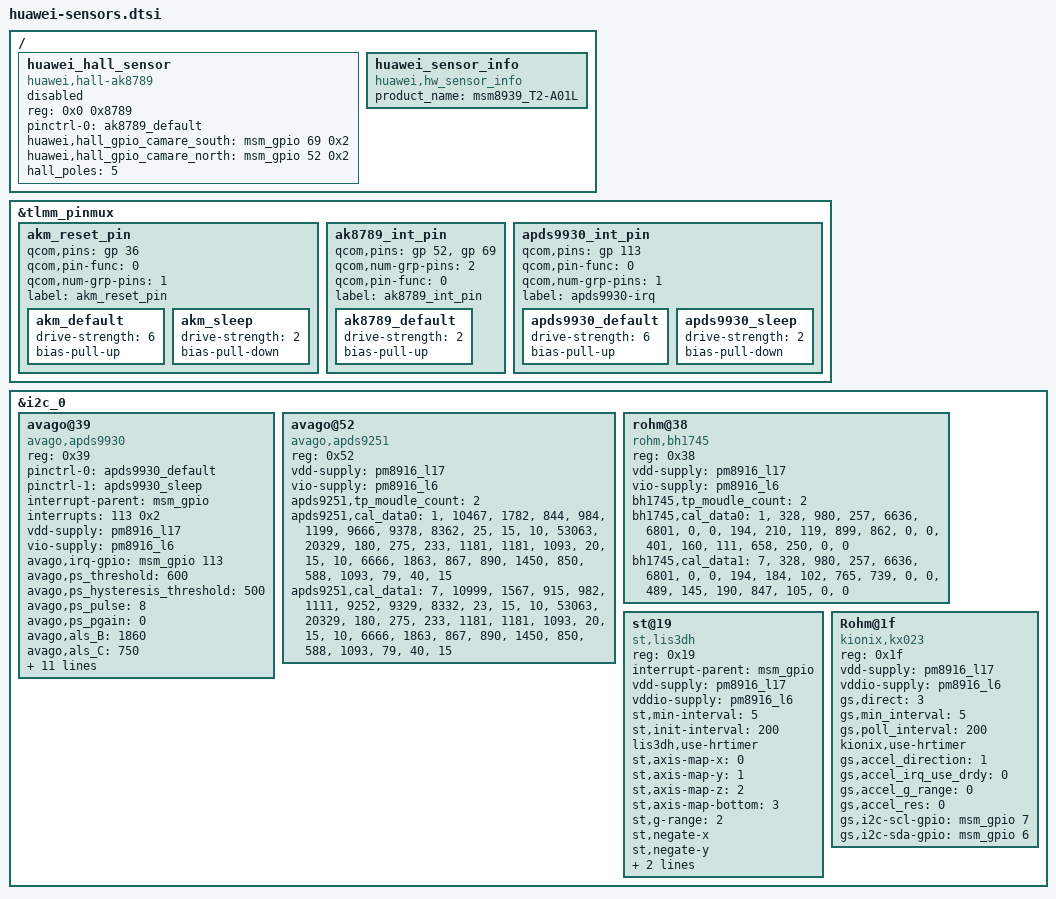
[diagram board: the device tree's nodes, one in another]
/* < DTS2015071605523 guotiecheng 20150716 begin */
/*use fromdos convert file format to linux*/
/* Copyright (c) 2013 The Linux Foundation. All rights reserved.
 *
 * This program is free software; you can redistribute it and/or modify
 * it under the terms of the GNU General Public License version 2 and
 * only version 2 as published by the Free Software Foundation.
 *
 * This program is distributed in the hope that it will be useful,
 * but WITHOUT ANY WARRANTY; without even the implied warranty of
 * MERCHANTABILITY or FITNESS FOR A PARTICULAR PURPOSE.  See the
 * GNU General Public License for more details.
 */
&tlmm_pinmux {
	akm_reset_pin {
		qcom,pins = <&gp 36>;
		qcom,pin-func = <0>;
		qcom,num-grp-pins = <1>;
		label = "akm_reset_pin";
		akm_default: akm_default {
			drive-strength = <6>;
			bias-pull-up;
		};
		akm_sleep: akm_sleep {
			drive-strength = <2>;
			bias-pull-down;
		};
	};

/* DTS2015012910874 dingjingfeng 20150206 begin> */
//delete lines
/* DTS2015012910874 dingjingfeng 20150206 end> */
	ak8789_int_pin {
		qcom,pins = <&gp 52>, <&gp 69>;
		qcom,num-grp-pins = <2>;
		qcom,pin-func = <0>;
		label = "ak8789_int_pin";
		ak8789_default: ak8789_default {
			  drive-strength = <2>;
			  bias-pull-up;
		};
	};
	apds9930_int_pin {
		qcom,pins = <&gp 113>;
		qcom,pin-func = <0>;
		qcom,num-grp-pins = <1>;
		label = "apds9930-irq";
		apds9930_default: apds9930_default {
			drive-strength = <6>;
			bias-pull-up;
		};
		apds9930_sleep: apds9930_sleep {
			drive-strength = <2>;
			bias-pull-down;
		};
	};
	/*<DTS2015072101855 chendong cwx241705 begin  */
	//delete
	/*DTS2015072101855 chendong cwx241705 end>  */
/* < DTS2015011203894 Zhangbo 00166742 20150112 begin */
/* delete some lines */
/* DTS2015011203894 Zhangbo 00166742 20150112 end > */
};

&i2c_0 { /* BLSP1 QUP2 */
	/* < DTS2015120500346  chendong 20151126 begin */
	//delete line
	/* DTS2015120500346  chendong 20151126 end > */
	avago@39 {
		compatible = "avago,apds9930";
		reg = <0x39>;
		pinctrl-names = "default","sleep";
		pinctrl-0 = <&apds9930_default>;
		pinctrl-1 = <&apds9930_sleep>;
		interrupt-parent = <&msm_gpio>;
		interrupts = <113 0x2>;
		vdd-supply = <&pm8916_l17>;
		vio-supply = <&pm8916_l6>;
		avago,irq-gpio = <&msm_gpio 113 0x2>;
		avago,ps_threshold = <600>;
		avago,ps_hysteresis_threshold = <500>;
		avago,ps_pulse = <8>;
		avago,ps_pgain = <0>;
		avago,als_B = <1860>;
		avago,als_C = <750>;
		avago,als_D = <1290>;
		avago,ga_value = <48>;
	        avago,ga_a_value = <112>;
		avago,ga_c_value = <450>;
		avago,ga_d_value = <162>;
		avago,window = <110>;
		avago,wave = <84>;
		avago,ga_e_value = <220>;
		avago,ga_f_value = <43>;
		/* < DTS2015032800844 caowei 20150319 begin */
		avago,i2c-scl-gpio = <&msm_gpio 7 0x0>;
		avago,i2c-sda-gpio = <&msm_gpio 6 0x0>;
		/* DTS2015032800844 caowei 20150319 end > */
	};
/* < DTS2015081407714 chendong wx241705 begin */
/* < DTS2015120303924 liuanqi wx319287 begin */
/* < DTS2016011800604  liuanqi lwx319287 begin */
	avago@52 {
		compatible = "avago,apds9251";
		reg = <0x52>;
		vdd-supply = <&pm8916_l17>;
		vio-supply = <&pm8916_l6>;
		apds9251,tp_moudle_count = <2>;
		/*[module_id] gold [CCT_M] [CCT_N] [H] [A] [D] [LUX_P] [LUX_Q] [LUX_R] [cofficient0] [cofficient1] [cofficient2]*/
		apds9251,cal_data0 = "1","10467","1782","844","984","1199","9666","9378","8362","25","15","10",
		/*white [CCT_M] [CCT_N] [H] [A] [D] [LUX_P] [LUX_Q] [LUX_R] [cofficient0] [cofficient1] [cofficient2]*/
		"53063","20329","180","275","233","1181","1181","1093","20","15","10",
		/*black [CCT_M] [CCT_N] [H] [A] [D] [LUX_P] [LUX_Q] [LUX_R] [cofficient0] [cofficient1] [cofficient2]*/
		"6666","1863","867","890","1450","850","588","1093","79","40","15";
		/*[module_id] [CCT_M] [CCT_N] [H] [A] [D] [LUX_P] [LUX_Q] [LUX_R] [cofficient0] [cofficient1] [cofficient2]*/
		apds9251,cal_data1 = "7","10999","1567","915","982","1111","9252","9329","8332","23","15","10",
		/*[CCT_M] [CCT_N] [H] [A] [D] [LUX_P] [LUX_Q] [LUX_R] [cofficient0] [cofficient1] [cofficient2]*/
		"53063","20329","180","275","233","1181","1181","1093","20","15","10",
		/*[CCT_M] [CCT_N] [H] [A] [D] [LUX_P] [LUX_Q] [LUX_R] [cofficient0] [cofficient1] [cofficient2]*/
		"6666","1863","867","890","1450","850","588","1093","79","40","15";
	};
/* DTS2015081407714 chendong wx241705 end > */
	/*<DTS2015072101855 chendong cwx241705 begin  */
	rohm@38 {
	compatible = "rohm,bh1745";
	reg = <0x38>;
	vdd-supply = <&pm8916_l17>;
	vio-supply = <&pm8916_l6>;
	/* < DTS2015040700192 wushengyu 20150407 begin */
	 /* < DTS2015032301235 chenyang 20150423 begin */
	/* <DTS2015091605583 chendong cwx241705 begin */
	bh1745,tp_moudle_count = <2>;
	/*[module_id] [golden judge] r[0] r[1] g[0] g[1] b[0] b[1]*/
	bh1745,cal_data0 = "1","328","980","257","6636","6801","0","0",
	/*[white judge] r[0] r[1] g[0] g[1] b[0] b[1]*/
	"194","210","119","899","862","0","0",
	/*[black judge] r[0] r[1] g[0] g[1] b[0] b[1]*/
	"401","160","111","658","250","0","0";
	/*[module_id] [golden judge] r[0] r[1] g[0] g[1] b[0] b[1]*/
	bh1745,cal_data1 = "7","328","980","257","6636","6801","0","0",
	/*[white judge] r[0] r[1] g[0] g[1] b[0] b[1]*/
	"194","184","102","765","739","0","0",
	/*[black judge] r[0] r[1] g[0] g[1] b[0] b[1]*/
	"489","145","190","847","105","0","0";
	/* DTS2016011800604  liuanqi lwx319287 end > */
/* DTS2015120303924 liuanqi wx319287 end > */
        /* DTS2015091605583 chendong cwx241705 end >*/
        /* DTS2015032301235 chenyang 20150423 end > */
        /* DTS2015040700192 wushengyu 20150407 end > */
    };
	st@19 {
		compatible = "st,lis3dh";
		reg = <0x19>;
/* DTS2015012910874 dingjingfeng 20150206 begin> */
//delete lines
/* DTS2015012910874 dingjingfeng 20150206 end> */
	/*DTS2015072101855 chendong cwx241705 end>  */
		interrupt-parent = <&msm_gpio>;
		vdd-supply = <&pm8916_l17>;
		vddio-supply = <&pm8916_l6>;
		st,min-interval = <5>;
		st,init-interval = <200>;
		/*  DTS2015052009130 hufeng 20150601 end > */
		lis3dh,use-hrtimer;
		/* < DTS2015052009130 hufeng 20150601 begin */
		st,axis-map-x = <0>;
		st,axis-map-y = <1>;
		st,axis-map-z = <2>;
		/*1 is bottom and others means top*/
		/* <DTS2015072101855 chendong 20150812 begin */
		st,axis-map-bottom=<3>;
		/* DTS2015072101855 chendong 20150812 end> */
		st,g-range = <2>;
/* DTS2015012910874 dingjingfeng 20150206 begin> */
//delete lines
/* DTS2015012910874 dingjingfeng 20150206 end> */
		st,negate-x;
		st,negate-y;
		/* < DTS2015032800844 caowei 20150319 begin */
		st,i2c-scl-gpio = <&msm_gpio 7 0x0>;
		st,i2c-sda-gpio = <&msm_gpio 6 0x0>;
		/* DTS2015032800844 caowei 20150319 end > */
	};
	/*<DTS2015072101855 chendong cwx241705 begin  */
	Rohm@1f {
		compatible = "kionix,kx023";
		reg = <0x1f>;
/* DTS2015012910874 dingjingfeng 20150206 begin> */
//delete lines
/* DTS2015012910874 dingjingfeng 20150206 end> */
	/*DTS2015072101855 chendong cwx241705 end>  */
		vdd-supply = <&pm8916_l17>;
		vddio-supply = <&pm8916_l6>;
		/* < DTS2014042813729 yangzhonghua 20140428 begin */
/* DTS2015012910874 dingjingfeng 20150206 begin> */
//delete lines
/* DTS2015012910874 dingjingfeng 20150206 end> */
		/* DTS2014042813729  yangzhonghua 20140428 end > */
		/* < DTS2014102905500 chuguoliang 20141029 begin */
		/*1 is bottom and others means top*/
		/* <DTS2015072101855 chendong 20150812 begin */
		gs,direct = <3>;
		/* DTS2015072101855 chendong 20150812 end> */
		/* DTS2014102905500 chuguoliang 20141029 end > */
		gs,min_interval = <5>;
		gs,poll_interval = <200>;
		/* < DTS2015052009130 hufeng 20150601 begin */
		kionix,use-hrtimer;
		/*  DTS2015052009130 hufeng 20150601 end > */
		gs,accel_direction = <1>;
		gs,accel_irq_use_drdy = <0>;
		gs,accel_g_range = <0>;
		gs,accel_res = <0>;
		/* < DTS2015032800844 caowei 20150319 begin */
		gs,i2c-scl-gpio = <&msm_gpio 7 0x0>;
		gs,i2c-sda-gpio = <&msm_gpio 6 0x0>;
		/* DTS2015032800844 caowei 20150319 end > */
	};
	
/* < DTS2015011203894 Zhangbo 00166742 20150112 begin */
/* delete some lines */
/* DTS2015011203894 Zhangbo 00166742 20150112 end > */
};
/{
	huawei_hall_sensor{
		compatible = "huawei,hall-ak8789";
		reg = <0x0 0x8789>;
		pinctrl-names = "default";
		pinctrl-0 = <&ak8789_default>;
		/* < DTS2014122304450 wangcunyou 20141223 begin */
		huawei,hall_gpio_camare_south = <&msm_gpio 69 0x2>;
		huawei,hall_gpio_camare_north = <&msm_gpio 52 0x2>;
		hall_poles = <5>;
		/* DTS2014122304450 wangcunyou 20141222 end > */
                /* < DTS2015100906156 chendong WX241705 20151010 begin */ 
		status = "disabled";
                /* DTS2015100906156 chendong WX241705 20151010 end > */
	};
};
/* DTS2014121804508 wangcunyou 20141218 end > */
/*<DTS2015072101855 chendong cwx241705 begin  */
/* < DTS2015020511013 wangcunyou 20150205 begin */
/{
	huawei_sensor_info {
		compatible = "huawei,hw_sensor_info";
		product_name = "msm8939_T2-A01L";
	};
};
/* DTS2015020511013 wangcunyou 20150205 end > */
/*DTS2015072101855 chendong cwx241705 end>  */
/* DTS2015071605523 guotiecheng 20150716 end >*/
